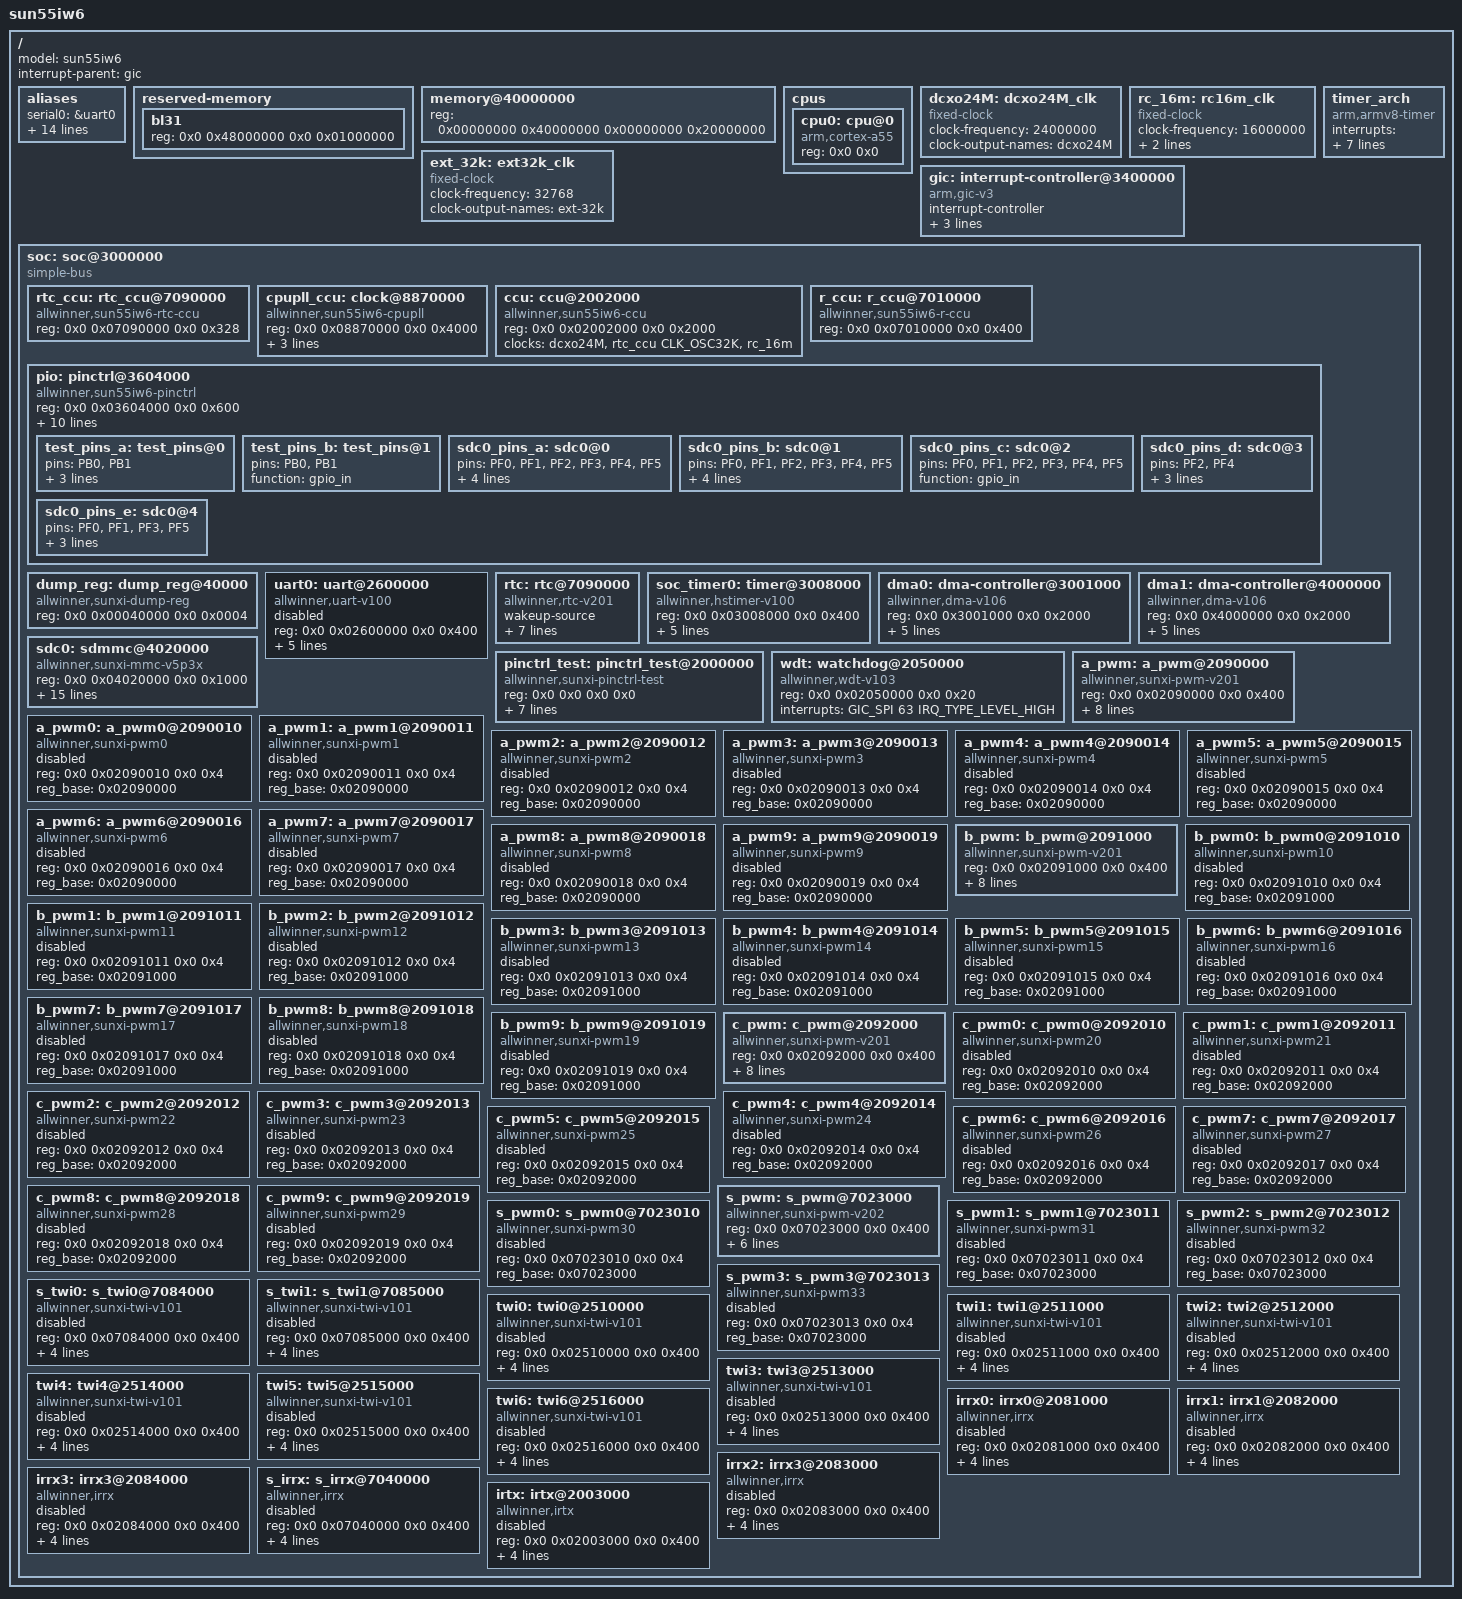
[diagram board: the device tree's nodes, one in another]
// SPDX-License-Identifier: (GPL-2.0+ or MIT)
#include <dt-bindings/clock/sun55iw6-ccu.h>
#include <dt-bindings/clock/sun55iw6-rtc.h>
#include <dt-bindings/clock/sun55iw6-r-ccu.h>
#include <dt-bindings/gpio/gpio.h>
#include <dt-bindings/gpio/sun4i-gpio.h>
#include <dt-bindings/interrupt-controller/arm-gic.h>
#include <dt-bindings/reset/sun55iw6-ccu.h>
#include <dt-bindings/reset/sun55iw6-r-ccu.h>
#include <dt-bindings/power/a523-power.h>
#include <dt-bindings/phy/phy.h>
#include <dt-bindings/thermal/thermal.h>

/ {
	model = "sun55iw6";
	interrupt-parent = <&gic>;
	#address-cells = <2>;
	#size-cells = <2>;

	aliases {
		serial0 = &uart0;
		twi0 = &twi0;
		twi1 = &twi1;
		twi2 = &twi2;
		twi3 = &twi3;
		twi4 = &twi4;
		twi5 = &twi5;
		twi6 = &twi6;
		twi7 = &s_twi0;
		twi8 = &s_twi1;
		ir0 = &irrx0;
		ir1 = &irrx1;
		ir2 = &irrx2;
		ir3 = &irrx3;
		ir4 = &s_irrx;
	};

	reserved-memory {
		#address-cells = <2>;
		#size-cells = <2>;
		ranges;

		bl31 {
			reg = <0x0 0x48000000 0x0 0x01000000>;
		};
	};

	/* avoid panic when memory-node err(from uboot) */
	memory@40000000 {
		device_type = "memory";
		reg = <0x00000000 0x40000000 0x00000000 0x20000000>;
	};

	cpus {
		#address-cells = <2>;
		#size-cells = <0>;

		cpu0: cpu@0 {
			device_type = "cpu";
			compatible = "arm,cortex-a55";
			reg = <0x0 0x0>;
		};
	};

	dcxo24M: dcxo24M_clk {
		#clock-cells = <0>;
		compatible = "fixed-clock";
		clock-frequency = <24000000>;
		clock-output-names = "dcxo24M";
	};

	rc_16m: rc16m_clk {
		#clock-cells = <0>;
		compatible = "fixed-clock";
		clock-frequency = <16000000>;
		clock-accuracy = <300000000>;
		clock-output-names = "rc-16m";
	};

	ext_32k: ext32k_clk {
		#clock-cells = <0>;
		compatible = "fixed-clock";
		clock-frequency = <32768>;
		clock-output-names = "ext-32k";
	};

	gic: interrupt-controller@3400000 {
		compatible = "arm,gic-v3";
		#interrupt-cells = <3>;
		#address-cells = <0>;
		interrupt-controller;
		reg = <0x0 0x03400000 0 0x10000>, /* GIC Dist */
		      <0x0 0x03460000 0 0xFF004>; /* GIC Re */
		interrupt-parent = <&gic>;
	};

	timer_arch {
		compatible = "arm,armv8-timer";
		interrupts = <GIC_PPI 13 (GIC_CPU_MASK_SIMPLE(4) | IRQ_TYPE_LEVEL_LOW)>,
			   <GIC_PPI 14 (GIC_CPU_MASK_SIMPLE(4) | IRQ_TYPE_LEVEL_LOW)>,
			   <GIC_PPI 11 (GIC_CPU_MASK_SIMPLE(4) | IRQ_TYPE_LEVEL_LOW)>,
			   <GIC_PPI 10 (GIC_CPU_MASK_SIMPLE(4) | IRQ_TYPE_LEVEL_LOW)>;
		clock-frequency = <24000000>;
		interrupt-parent = <&gic>;
		arm,no-tick-in-suspend;
	};

	soc: soc@3000000 {
		compatible = "simple-bus";
		#address-cells = <2>;
		#size-cells = <2>;
		ranges;

		rtc_ccu: rtc_ccu@7090000 {
			compatible = "allwinner,sun55iw6-rtc-ccu";
			reg = <0x0 0x07090000 0x0 0x328>;
			#clock-cells = <1>;
			#reset-cells = <1>;
		};

		cpupll_ccu: clock@8870000 {
			compatible = "allwinner,sun55iw6-cpupll";
			reg = <0x0 0x08870000 0x0 0x4000>;
			#clock-cells = <1>;
			#reset-cells = <1>;
			pll_step = <0x9>;
			/* pll_ssc will divid pll_ssc_scale in code
			 * keep value 0 < pll_ssc < 10
			 */
			pll_ssc_scale = <0xa>;
			pll_ssc = <0x1>;
		};

		ccu: ccu@2002000 {
			compatible = "allwinner,sun55iw6-ccu";
			reg = <0x0 0x02002000 0x0 0x2000>;
			clocks = <&dcxo24M>, <&rtc_ccu CLK_OSC32K>, <&rc_16m>;
			clock-names = "hosc", "losc", "iosc";
			#clock-cells = <1>;
			#reset-cells = <1>;
		};

		r_ccu: r_ccu@7010000 {
			compatible = "allwinner,sun55iw6-r-ccu";
			reg = <0x0 0x07010000 0x0 0x400>;
			#clock-cells = <1>;
			#reset-cells = <1>;
		};

		pio: pinctrl@3604000 {
			//#address-cells = <1>;
			//#size-cells = <0>;
			compatible = "allwinner,sun55iw6-pinctrl";
			reg = <0x0 0x03604000 0x0 0x600>;
			interrupts = <GIC_SPI 67 IRQ_TYPE_LEVEL_HIGH>,
				     <GIC_SPI 69 IRQ_TYPE_LEVEL_HIGH>,
				     <GIC_SPI 71 IRQ_TYPE_LEVEL_HIGH>,
				     <GIC_SPI 73 IRQ_TYPE_LEVEL_HIGH>,
				     <GIC_SPI 77 IRQ_TYPE_LEVEL_HIGH>,
				     <GIC_SPI 79 IRQ_TYPE_LEVEL_HIGH>;
			clocks = <&ccu CLK_APB1>, <&dcxo24M>, <&rtc_ccu CLK_OSC32K>;
			clock-names = "apb", "hosc", "losc";
			gpio-controller;
			#gpio-cells = <3>;
			interrupt-controller;
			#interrupt-cells = <3>;

			test_pins_a: test_pins@0 {
				pins = "PB0", "PB1";
				function = "test";
				drive-strength = <10>;
				bias-pull-up;
			};

			test_pins_b: test_pins@1 {
				pins = "PB0", "PB1";
				function = "gpio_in";
			};

			sdc0_pins_a: sdc0@0 {
				pins = "PF0", "PF1", "PF2",
						"PF3", "PF4", "PF5";
				function = "sdc0";
				drive-strength = <40>;
				bias-pull-up;
				power-source = <3300>;
			};

			sdc0_pins_b: sdc0@1 {
				pins = "PF0", "PF1", "PF2",
						"PF3", "PF4", "PF5";
				function = "sdc0";
				drive-strength = <40>;
				bias-pull-up;
				power-source = <1800>;
			};

			sdc0_pins_c: sdc0@2 {
				pins = "PF0", "PF1", "PF2",
				"PF3", "PF4", "PF5";
				function = "gpio_in";
			};

			/* TODO: add jtag pin */
			sdc0_pins_d: sdc0@3 {
				pins = "PF2", "PF4";
				function = "uart0";
				drive-strength = <10>;
				bias-pull-up;
			};

			sdc0_pins_e: sdc0@4 {
				pins = "PF0", "PF1", "PF3",
						"PF5";
				function = "jtag";
				drive-strength = <10>;
				bias-pull-up;
			};
		};

		dump_reg: dump_reg@40000 {
			compatible = "allwinner,sunxi-dump-reg";
			reg = <0x0 0x00040000 0x0 0x0004>;
		};

		uart0: uart@2600000 {
			compatible = "allwinner,uart-v100";
			reg = <0x0 0x02600000 0x0 0x400>;
			interrupts = <GIC_SPI 2 IRQ_TYPE_LEVEL_HIGH>;
			clocks = <&ccu CLK_BUS_UART0>;
			resets = <&ccu RST_BUS_UART0>;
			uart0_port = <0>;
			uart0_type = <2>;
			status = "disabled";
		};

		rtc: rtc@7090000 {
			compatible = "allwinner,rtc-v201";
			device_type = "rtc";
			wakeup-source;
			reg = <0x0 0x07090000 0x0 0x320>;
			interrupts = <GIC_SPI 200 IRQ_TYPE_LEVEL_HIGH>;
			clocks = <&r_ccu CLK_RTC>, <&rtc_ccu CLK_RTC_1K>, <&rtc_ccu CLK_RTC_SPI>;
			clock-names = "r-ahb-rtc", "rtc-1k", "rtc-spi";
			resets = <&r_ccu RST_BUS_RTC>;
			gpr_cur_pos = <6>;
			gpr_bootcount_pos = <7>;
		};

		soc_timer0: timer@3008000 {
			compatible = "allwinner,hstimer-v100";
			device_type = "soc_timer";
			reg = <0x0 0x03008000 0x0 0x400>;
			interrupt-parent = <&gic>;
			interrupts = <GIC_SPI 55 IRQ_TYPE_LEVEL_HIGH>;
			clock-names = "parent", "bus", "timer0-mod", "timer1-mod";
			clocks = <&dcxo24M>, <&ccu CLK_BUS_TIMER>, <&ccu CLK_TIMER0>, <&ccu CLK_TIMER1>;
			resets = <&ccu RST_BUS_TIME>;
		};

		dma0: dma-controller@3001000 {
			compatible = "allwinner,dma-v106";
			reg = <0x0 0x3001000 0x0 0x2000>;
			interrupts = <GIC_SPI 50 IRQ_TYPE_LEVEL_HIGH>;
			clocks = <&ccu CLK_DMA0>, <&ccu CLK_DMA0_MBUS_GATE>;
			clock-names = "bus", "mbus";
			dma-channels = <16>;
			dma-requests = <64>;
			resets = <&ccu RST_BUS_DMA0>;
			#dma-cells = <1>;
		};

		dma1: dma-controller@4000000 {
			compatible = "allwinner,dma-v106";
			reg = <0x0 0x4000000 0x0 0x2000>;
			interrupts = <GIC_SPI 168 IRQ_TYPE_LEVEL_HIGH>;
			clocks = <&ccu CLK_DMA1>, <&ccu CLK_DMA1_MBUS_GATE>;
			clock-names = "bus", "mbus";
			dma-channels = <16>;
			dma-requests = <64>;
			resets = <&ccu RST_BUS_DMA1>;
			#dma-cells = <1>;
		};

		pinctrl_test: pinctrl_test@2000000 {
		      reg = <0x0 0x0 0x0 0x0>;
		      compatible = "allwinner,sunxi-pinctrl-test";
		      device_type = "pinctrl-test";
		      pinctrl-0 = <&test_pins_a>;
		      pinctrl-1 = <&test_pins_b>;
		      pinctrl-names = "default", "sleep";
		      test-gpios = <&pio PB 4 GPIO_ACTIVE_LOW>;
		      suspend-gpios = <&pio PB 5 GPIO_ACTIVE_LOW>;
		      wakeup-source;
		      interrupt-parent = <&pio>;
		      interrupts = <PB 6 IRQ_TYPE_LEVEL_HIGH>;
		};

		wdt: watchdog@2050000 {
			compatible = "allwinner,wdt-v103";
			reg = <0x0 0x02050000 0x0 0x20>;
			interrupts = <GIC_SPI 63 IRQ_TYPE_LEVEL_HIGH>;  /* In GIC Spec */
		};

		sdc0: sdmmc@4020000 {
			compatible = "allwinner,sunxi-mmc-v5p3x";
			device_type = "sdc0";
			reg = <0x0 0x04020000 0x0 0x1000>;
			interrupts = <GIC_SPI 40 IRQ_TYPE_LEVEL_HIGH>;
						clocks = <&dcxo24M>,
						<&ccu CLK_PLL_PERI1_400M>,
						<&ccu CLK_PLL_PERI1_300M>,
						<&ccu CLK_SMHC0>,
						<&ccu CLK_BUS_SMHC0>;
			clock-names = "osc24m","pll_periph","pll_periph_2","mmc","ahb";
			resets = <&ccu RST_BUS_SMHC0>;
			reset-names = "rst";
			pinctrl-names = "default","mmc_1v8","sleep","uart_jtag";
			pinctrl-0 = <&sdc0_pins_a>;
			pinctrl-1 = <&sdc0_pins_b>;
			pinctrl-2 = <&sdc0_pins_c>;
			pinctrl-3 = <&sdc0_pins_d &sdc0_pins_e>;
			max-frequency = <50000000>;
			bus-width = <4>;
			req-page-count = <2>;
			/*non-removable;*/
			/*broken-cd;*/
			/*cd-inverted*/
			/*cd-gpios = <&pio PF 6 GPIO_ACTIVE_LOW>;*/
			/* vmmc-supply = <&reg_3p3v>;*/
			/* vqmc-supply = <&reg_3p3v>;*/
			/* vdmc-supply = <&reg_3p3v>;*/
			/*vmmc = "vcc-card";*/
			/*vqmc = "";*/
			/*vdmc = "";*/
			cap-sd-highspeed;
			cap-wait-while-busy;
			/*sd-uhs-sdr50;*/
			/*sd-uhs-ddr50;*/
			/*cap-sdio-irq;*/
			/*keep-power-in-suspend;*/
			/*ignore-pm-notify;*/
			/*sunxi-power-save-mode;*/
			/*sunxi-dly-400k = <1 0 0 0>; */
			/*sunxi-dly-26M  = <1 0 0 0>;*/
			/*sunxi-dly-52M  = <1 0 0 0>;*/
			/*sunxi-dly-52M-ddr4  = <1 0 0 0>;*/
			/*sunxi-dly-52M-ddr8  = <1 0 0 0>;*/
			/*sunxi-dly-104M  = <1 0 0 0>;*/
			/*sunxi-dly-208M  = <1 0 0 0>;*/
			/*sunxi-dly-104M-ddr  = <1 0 0 0>;*/
			/*sunxi-dly-208M-ddr  = <1 0 0 0>;*/
			ctl-spec-caps = <0x408>;
			status = "okay";
		};

		a_pwm: a_pwm@2090000 {
			#pwm-cells = <0x3>;
			compatible = "allwinner,sunxi-pwm-v201";
			reg = <0x0 0x02090000 0x0 0x400>;
			clocks = <&ccu CLK_PWM0>;
			interrupts = <GIC_SPI 19 IRQ_TYPE_LEVEL_HIGH>;
			resets = <&ccu RST_BUS_PWM0>;
			pwm-number = <10>;
			pwm-base = <0x0>;
			sunxi-pwms = <&a_pwm0>, <&a_pwm1>, <&a_pwm2>, <&a_pwm3>, <&a_pwm4>,
			<&a_pwm5>, <&a_pwm6>, <&a_pwm7>, <&a_pwm8>, <&a_pwm9>;
			status = "okay";
		};

		a_pwm0: a_pwm0@2090010 {
			compatible = "allwinner,sunxi-pwm0";
			reg = <0x0 0x02090010 0x0 0x4>;
			reg_base = <0x02090000>;
			status = "disabled";
		};

		a_pwm1: a_pwm1@2090011 {
			compatible = "allwinner,sunxi-pwm1";
			reg = <0x0 0x02090011 0x0 0x4>;
			reg_base = <0x02090000>;
			status = "disabled";
		};

		a_pwm2: a_pwm2@2090012 {
			compatible = "allwinner,sunxi-pwm2";
			reg = <0x0 0x02090012 0x0 0x4>;
			reg_base = <0x02090000>;
			status = "disabled";
		};

		a_pwm3: a_pwm3@2090013 {
			compatible = "allwinner,sunxi-pwm3";
			reg = <0x0 0x02090013 0x0 0x4>;
			reg_base = <0x02090000>;
			status = "disabled";
		};

		a_pwm4: a_pwm4@2090014 {
			compatible = "allwinner,sunxi-pwm4";
			reg = <0x0 0x02090014 0x0 0x4>;
			reg_base = <0x02090000>;
			status = "disabled";
		};

		a_pwm5: a_pwm5@2090015 {
			compatible = "allwinner,sunxi-pwm5";
			reg = <0x0 0x02090015 0x0 0x4>;
			reg_base = <0x02090000>;
			status = "disabled";
		};

		a_pwm6: a_pwm6@2090016 {
			compatible = "allwinner,sunxi-pwm6";
			reg = <0x0 0x02090016 0x0 0x4>;
			reg_base = <0x02090000>;
			status = "disabled";
		};

		a_pwm7: a_pwm7@2090017 {
			compatible = "allwinner,sunxi-pwm7";
			reg = <0x0 0x02090017 0x0 0x4>;
			reg_base = <0x02090000>;
			status = "disabled";
		};

		a_pwm8: a_pwm8@2090018 {
			compatible = "allwinner,sunxi-pwm8";
			reg = <0x0 0x02090018 0x0 0x4>;
			reg_base = <0x02090000>;
			status = "disabled";
		};

		a_pwm9: a_pwm9@2090019 {
			compatible = "allwinner,sunxi-pwm9";
			reg = <0x0 0x02090019 0x0 0x4>;
			reg_base = <0x02090000>;
			status = "disabled";
		};

		b_pwm: b_pwm@2091000 {
			#pwm-cells = <0x3>;
			compatible = "allwinner,sunxi-pwm-v201";
			reg = <0x0 0x02091000 0x0 0x400>;
			clocks = <&ccu CLK_PWM1>;
			interrupts = <GIC_SPI 142 IRQ_TYPE_LEVEL_HIGH>;
			resets = <&ccu RST_BUS_PWM1>;
			pwm-number = <10>;
			pwm-base = <0xa>;
			sunxi-pwms = <&b_pwm0>, <&b_pwm1>, <&b_pwm2>, <&b_pwm3>,
			<&b_pwm4>, <&b_pwm5>, <&b_pwm6>, <&b_pwm7>, <&b_pwm8>, <&b_pwm9>;
			status = "okay";
		};

		b_pwm0: b_pwm0@2091010 {
			compatible = "allwinner,sunxi-pwm10";
			reg = <0x0 0x02091010 0x0 0x4>;
			reg_base = <0x02091000>;
			status = "disabled";
		};

		b_pwm1: b_pwm1@2091011 {
			compatible = "allwinner,sunxi-pwm11";
			reg = <0x0 0x02091011 0x0 0x4>;
			reg_base = <0x02091000>;
			status = "disabled";
		};

		b_pwm2: b_pwm2@2091012 {
			compatible = "allwinner,sunxi-pwm12";
			reg = <0x0 0x02091012 0x0 0x4>;
			reg_base = <0x02091000>;
			status = "disabled";
		};

		b_pwm3: b_pwm3@2091013 {
			compatible = "allwinner,sunxi-pwm13";
			reg = <0x0 0x02091013 0x0 0x4>;
			reg_base = <0x02091000>;
			status = "disabled";
		};

		b_pwm4: b_pwm4@2091014 {
			compatible = "allwinner,sunxi-pwm14";
			reg = <0x0 0x02091014 0x0 0x4>;
			reg_base = <0x02091000>;
			status = "disabled";
		};

		b_pwm5: b_pwm5@2091015 {
			compatible = "allwinner,sunxi-pwm15";
			reg = <0x0 0x02091015 0x0 0x4>;
			reg_base = <0x02091000>;
			status = "disabled";
		};

		b_pwm6: b_pwm6@2091016 {
			compatible = "allwinner,sunxi-pwm16";
			reg = <0x0 0x02091016 0x0 0x4>;
			reg_base = <0x02091000>;
			status = "disabled";
		};

		b_pwm7: b_pwm7@2091017 {
			compatible = "allwinner,sunxi-pwm17";
			reg = <0x0 0x02091017 0x0 0x4>;
			reg_base = <0x02091000>;
			status = "disabled";
		};

		b_pwm8: b_pwm8@2091018 {
			compatible = "allwinner,sunxi-pwm18";
			reg = <0x0 0x02091018 0x0 0x4>;
			reg_base = <0x02091000>;
			status = "disabled";
		};

		b_pwm9: b_pwm9@2091019 {
			compatible = "allwinner,sunxi-pwm19";
			reg = <0x0 0x02091019 0x0 0x4>;
			reg_base = <0x02091000>;
			status = "disabled";
		};

		c_pwm: c_pwm@2092000 {
			#pwm-cells = <0x3>;
			compatible = "allwinner,sunxi-pwm-v201";
			reg = <0x0 0x02092000 0x0 0x400>;
			clocks = <&ccu CLK_PWM2>;
			interrupts = <GIC_SPI 211 IRQ_TYPE_LEVEL_HIGH>;
			resets = <&ccu RST_BUS_PWM2>;
			pwm-number = <10>;
			pwm-base = <0x14>;
			sunxi-pwms = <&c_pwm0>, <&c_pwm1>, <&c_pwm2>, <&c_pwm3>,
			<&c_pwm4>, <&c_pwm5>, <&c_pwm6>, <&c_pwm7>, <&c_pwm8>, <&c_pwm9>;
			status = "okay";
		};

		c_pwm0: c_pwm0@2092010 {
			compatible = "allwinner,sunxi-pwm20";
			reg = <0x0 0x02092010 0x0 0x4>;
			reg_base = <0x02092000>;
			status = "disabled";
		};

		c_pwm1: c_pwm1@2092011 {
			compatible = "allwinner,sunxi-pwm21";
			reg = <0x0 0x02092011 0x0 0x4>;
			reg_base = <0x02092000>;
			status = "disabled";
		};

		c_pwm2: c_pwm2@2092012 {
			compatible = "allwinner,sunxi-pwm22";
			reg = <0x0 0x02092012 0x0 0x4>;
			reg_base = <0x02092000>;
			status = "disabled";
		};

		c_pwm3: c_pwm3@2092013 {
			compatible = "allwinner,sunxi-pwm23";
			reg = <0x0 0x02092013 0x0 0x4>;
			reg_base = <0x02092000>;
			status = "disabled";
		};

		c_pwm4: c_pwm4@2092014 {
			compatible = "allwinner,sunxi-pwm24";
			reg = <0x0 0x02092014 0x0 0x4>;
			reg_base = <0x02092000>;
			status = "disabled";
		};

		c_pwm5: c_pwm5@2092015 {
			compatible = "allwinner,sunxi-pwm25";
			reg = <0x0 0x02092015 0x0 0x4>;
			reg_base = <0x02092000>;
			status = "disabled";
		};

		c_pwm6: c_pwm6@2092016 {
			compatible = "allwinner,sunxi-pwm26";
			reg = <0x0 0x02092016 0x0 0x4>;
			reg_base = <0x02092000>;
			status = "disabled";
		};

		c_pwm7: c_pwm7@2092017 {
			compatible = "allwinner,sunxi-pwm27";
			reg = <0x0 0x02092017 0x0 0x4>;
			reg_base = <0x02092000>;
			status = "disabled";
		};

		c_pwm8: c_pwm8@2092018 {
			compatible = "allwinner,sunxi-pwm28";
			reg = <0x0 0x02092018 0x0 0x4>;
			reg_base = <0x02092000>;
			status = "disabled";
		};

		c_pwm9: c_pwm9@2092019 {
			compatible = "allwinner,sunxi-pwm29";
			reg = <0x0 0x02092019 0x0 0x4>;
			reg_base = <0x02092000>;
			status = "disabled";
		};

		s_pwm: s_pwm@7023000 {
			#pwm-cells = <0x3>;
			compatible = "allwinner,sunxi-pwm-v202";
			reg = <0x0 0x07023000 0x0 0x400>;
			clocks = <&r_ccu CLK_R_PWM>,<&r_ccu CLK_R_BUS_PWM>;
			interrupts = <GIC_SPI 207 IRQ_TYPE_LEVEL_HIGH>;
			clock-names = "clk_pwm","clk_bus_pwm";
			resets = <&r_ccu RST_BUS_R_PWM>;
			pwm-number = <4>;
			pwm-base = <0x1e>;
			sunxi-pwms = <&s_pwm0>, <&s_pwm1>, <&s_pwm2>, <&s_pwm3>;
			status = "okay";
		};

		s_pwm0: s_pwm0@7023010 {
			compatible = "allwinner,sunxi-pwm30";
			reg = <0x0 0x07023010 0x0 0x4>;
			reg_base = <0x07023000>;
			status = "disabled";
		};

		s_pwm1: s_pwm1@7023011 {
			compatible = "allwinner,sunxi-pwm31";
			reg = <0x0 0x07023011 0x0 0x4>;
			reg_base = <0x07023000>;
			status = "disabled";
		};

		s_pwm2: s_pwm2@7023012 {
			compatible = "allwinner,sunxi-pwm32";
			reg = <0x0 0x07023012 0x0 0x4>;
			reg_base = <0x07023000>;
			status = "disabled";
		};

		s_pwm3: s_pwm3@7023013 {
			compatible = "allwinner,sunxi-pwm33";
			reg = <0x0 0x07023013 0x0 0x4>;
			reg_base = <0x07023000>;
			status = "disabled";
		};

		s_twi0: s_twi0@7084000 {
			#address-cells = <1>;
			#size-cells = <0>;
			compatible = "allwinner,sunxi-twi-v101";
			device_type = "s_twi0";
			reg = <0x0 0x07084000 0x0 0x400>;
			interrupts = <GIC_SPI 207 IRQ_TYPE_LEVEL_HIGH>;
			clocks = <&r_ccu CLK_R_TWI0>;
			clock-names = "bus";
			resets = <&r_ccu RST_BUS_R_TWI0>;
			dmas = <&dma0 49>, <&dma0 49>;
			dma-names = "tx", "rx";
			status = "disabled";
		};

		s_twi1: s_twi1@7085000 {
			#address-cells = <1>;
			#size-cells = <0>;
			compatible = "allwinner,sunxi-twi-v101";
			device_type = "s_twi1";
			reg = <0x0 0x07085000 0x0 0x400>;
			interrupts = <GIC_SPI 208 IRQ_TYPE_LEVEL_HIGH>;
			clocks = <&r_ccu CLK_R_TWI1>;
			clock-names = "bus";
			resets = <&r_ccu RST_BUS_R_TWI1>;
			dmas = <&dma0 50>, <&dma0 50>;
			dma-names = "tx", "rx";
			status = "disabled";
		};

		twi0: twi0@2510000 {
			#address-cells = <1>;
			#size-cells = <0>;
			compatible = "allwinner,sunxi-twi-v101";
			device_type = "twi0";
			reg = <0x0 0x02510000 0x0 0x400>;
			interrupts = <GIC_SPI 10 IRQ_TYPE_LEVEL_HIGH>;
			clocks = <&ccu CLK_TWI0>;
			clock-names = "bus";
			resets = <&ccu RST_BUS_TWI0>;
			dmas = <&dma0 43>, <&dma0 43>;
			dma-names = "tx", "rx";
			status = "disabled";
		};

		twi1: twi1@2511000 {
			#address-cells = <1>;
			#size-cells = <0>;
			compatible = "allwinner,sunxi-twi-v101";
			device_type = "twi1";
			reg = <0x0 0x02511000 0x0 0x400>;
			interrupts = <GIC_SPI 11 IRQ_TYPE_LEVEL_HIGH>;
			clocks = <&ccu CLK_TWI1>;
			clock-names = "bus";
			resets = <&ccu RST_BUS_TWI1>;
			dmas = <&dma0 44>, <&dma0 44>;
			dma-names = "tx", "rx";
			status = "disabled";
		};

		twi2: twi2@2512000 {
			#address-cells = <1>;
			#size-cells = <0>;
			compatible = "allwinner,sunxi-twi-v101";
			device_type = "twi2";
			reg = <0x0 0x02512000 0x0 0x400>;
			interrupts = <GIC_SPI 12 IRQ_TYPE_LEVEL_HIGH>;
			clocks = <&ccu CLK_TWI2>;
			clock-names = "bus";
			resets = <&ccu RST_BUS_TWI2>;
			dmas = <&dma0 45>, <&dma0 45>;
			dma-names = "tx", "rx";
			status = "disabled";
		};

		twi3: twi3@2513000 {
			#address-cells = <1>;
			#size-cells = <0>;
			compatible = "allwinner,sunxi-twi-v101";
			device_type = "twi3";
			reg = <0x0 0x02513000 0x0 0x400>;
			interrupts = <GIC_SPI 13 IRQ_TYPE_LEVEL_HIGH>;
			clocks = <&ccu CLK_TWI3>;
			clock-names = "bus";
			resets = <&ccu RST_BUS_TWI3>;
			dmas = <&dma0 46>, <&dma0 46>;
			dma-names = "tx", "rx";
			status = "disabled";
		};

		twi4: twi4@2514000 {
			#address-cells = <1>;
			#size-cells = <0>;
			compatible = "allwinner,sunxi-twi-v101";
			device_type = "twi4";
			reg = <0x0 0x02514000 0x0 0x400>;
			interrupts = <GIC_SPI 14 IRQ_TYPE_LEVEL_HIGH>;
			clocks = <&ccu CLK_TWI4>;
			clock-names = "bus";
			resets = <&ccu RST_BUS_TWI4>;
			dmas = <&dma0 47>, <&dma0 47>;
			dma-names = "tx", "rx";
			status = "disabled";
		};

		twi5: twi5@2515000 {
			#address-cells = <1>;
			#size-cells = <0>;
			compatible = "allwinner,sunxi-twi-v101";
			device_type = "twi5";
			reg = <0x0 0x02515000 0x0 0x400>;
			interrupts = <GIC_SPI 15 IRQ_TYPE_LEVEL_HIGH>;
			clocks = <&ccu CLK_TWI5>;
			clock-names = "bus";
			resets = <&ccu RST_BUS_TWI5>;
			dmas = <&dma0 48>, <&dma0 48>;
			dma-names = "tx", "rx";
			status = "disabled";
		};

		twi6: twi6@2516000 {
			#address-cells = <1>;
			#size-cells = <0>;
			compatible = "allwinner,sunxi-twi-v101";
			device_type = "twi6";
			reg = <0x0 0x02516000 0x0 0x400>;
			interrupts = <GIC_SPI 155 IRQ_TYPE_LEVEL_HIGH>;
			clocks = <&ccu CLK_TWI6>;
			clock-names = "bus";
			resets = <&ccu RST_BUS_TWI6>;
			dmas = <&dma0 62>, <&dma0 62>;
			dma-names = "tx", "rx";
			status = "disabled";
		};

		irrx0: irrx0@2081000 {
			compatible = "allwinner,irrx";
			reg = <0x0 0x02081000 0x0 0x400>;
			interrupts = <GIC_SPI 27 IRQ_TYPE_LEVEL_HIGH>;
			clocks = <&ccu CLK_BUS_IRRX0>, <&dcxo24M>, <&ccu CLK_IRRX0>;
			clock-names = "bus", "pclk", "mclk";
			resets = <&ccu RST_BUS_IRRX0>;
			status = "disabled";
		};

		irrx1: irrx1@2082000 {
			compatible = "allwinner,irrx";
			reg = <0x0 0x02082000 0x0 0x400>;
			interrupts = <GIC_SPI 117 IRQ_TYPE_LEVEL_HIGH>;
			clocks = <&ccu CLK_BUS_IRRX1>, <&dcxo24M>, <&ccu CLK_IRRX1>;
			clock-names = "bus", "pclk", "mclk";
			resets = <&ccu RST_BUS_IRRX1>;
			status = "disabled";
		};

		irrx2: irrx3@2083000 {
			compatible = "allwinner,irrx";
			reg = <0x0 0x02083000 0x0 0x400>;
			interrupts = <GIC_SPI 118 IRQ_TYPE_LEVEL_HIGH>;
			clocks = <&ccu CLK_BUS_IRRX2>, <&dcxo24M>, <&ccu CLK_IRRX2>;
			clock-names = "bus", "pclk", "mclk";
			resets = <&ccu RST_BUS_IRRX2>;
			status = "disabled";
		};

		irrx3: irrx3@2084000 {
			compatible = "allwinner,irrx";
			reg = <0x0 0x02084000 0x0 0x400>;
			interrupts = <GIC_SPI 119 IRQ_TYPE_LEVEL_HIGH>;
			clocks = <&ccu CLK_BUS_IRRX3>, <&dcxo24M>, <&ccu CLK_IRRX3>;
			clock-names = "bus", "pclk", "mclk";
			resets = <&ccu RST_BUS_IRRX3>;
			status = "disabled";
		};

		s_irrx: s_irrx@7040000 {
			compatible = "allwinner,irrx";
			reg = <0x0 0x07040000 0x0 0x400>;
			interrupts = <GIC_SPI 210 IRQ_TYPE_LEVEL_HIGH>;
			clocks = <&r_ccu CLK_R_BUS_IRRX>, <&dcxo24M>, <&r_ccu CLK_R_IRRX>;
			clock-names = "bus", "pclk", "mclk";
			resets = <&r_ccu RST_BUS_R_IRRX>;
			status = "disabled";
		};

		irtx: irtx@2003000 {
			compatible = "allwinner,irtx";
			reg = <0x0 0x02003000 0x0 0x400>;
			interrupts = <GIC_SPI 26 IRQ_TYPE_LEVEL_HIGH>;
			clocks = <&ccu CLK_BUS_IRTX>, <&dcxo24M>, <&ccu CLK_IRTX>;
			clock-names = "bus", "pclk", "mclk";
			resets = <&ccu RST_BUS_IRTX>;
			status = "disabled";
		};
	};
};

